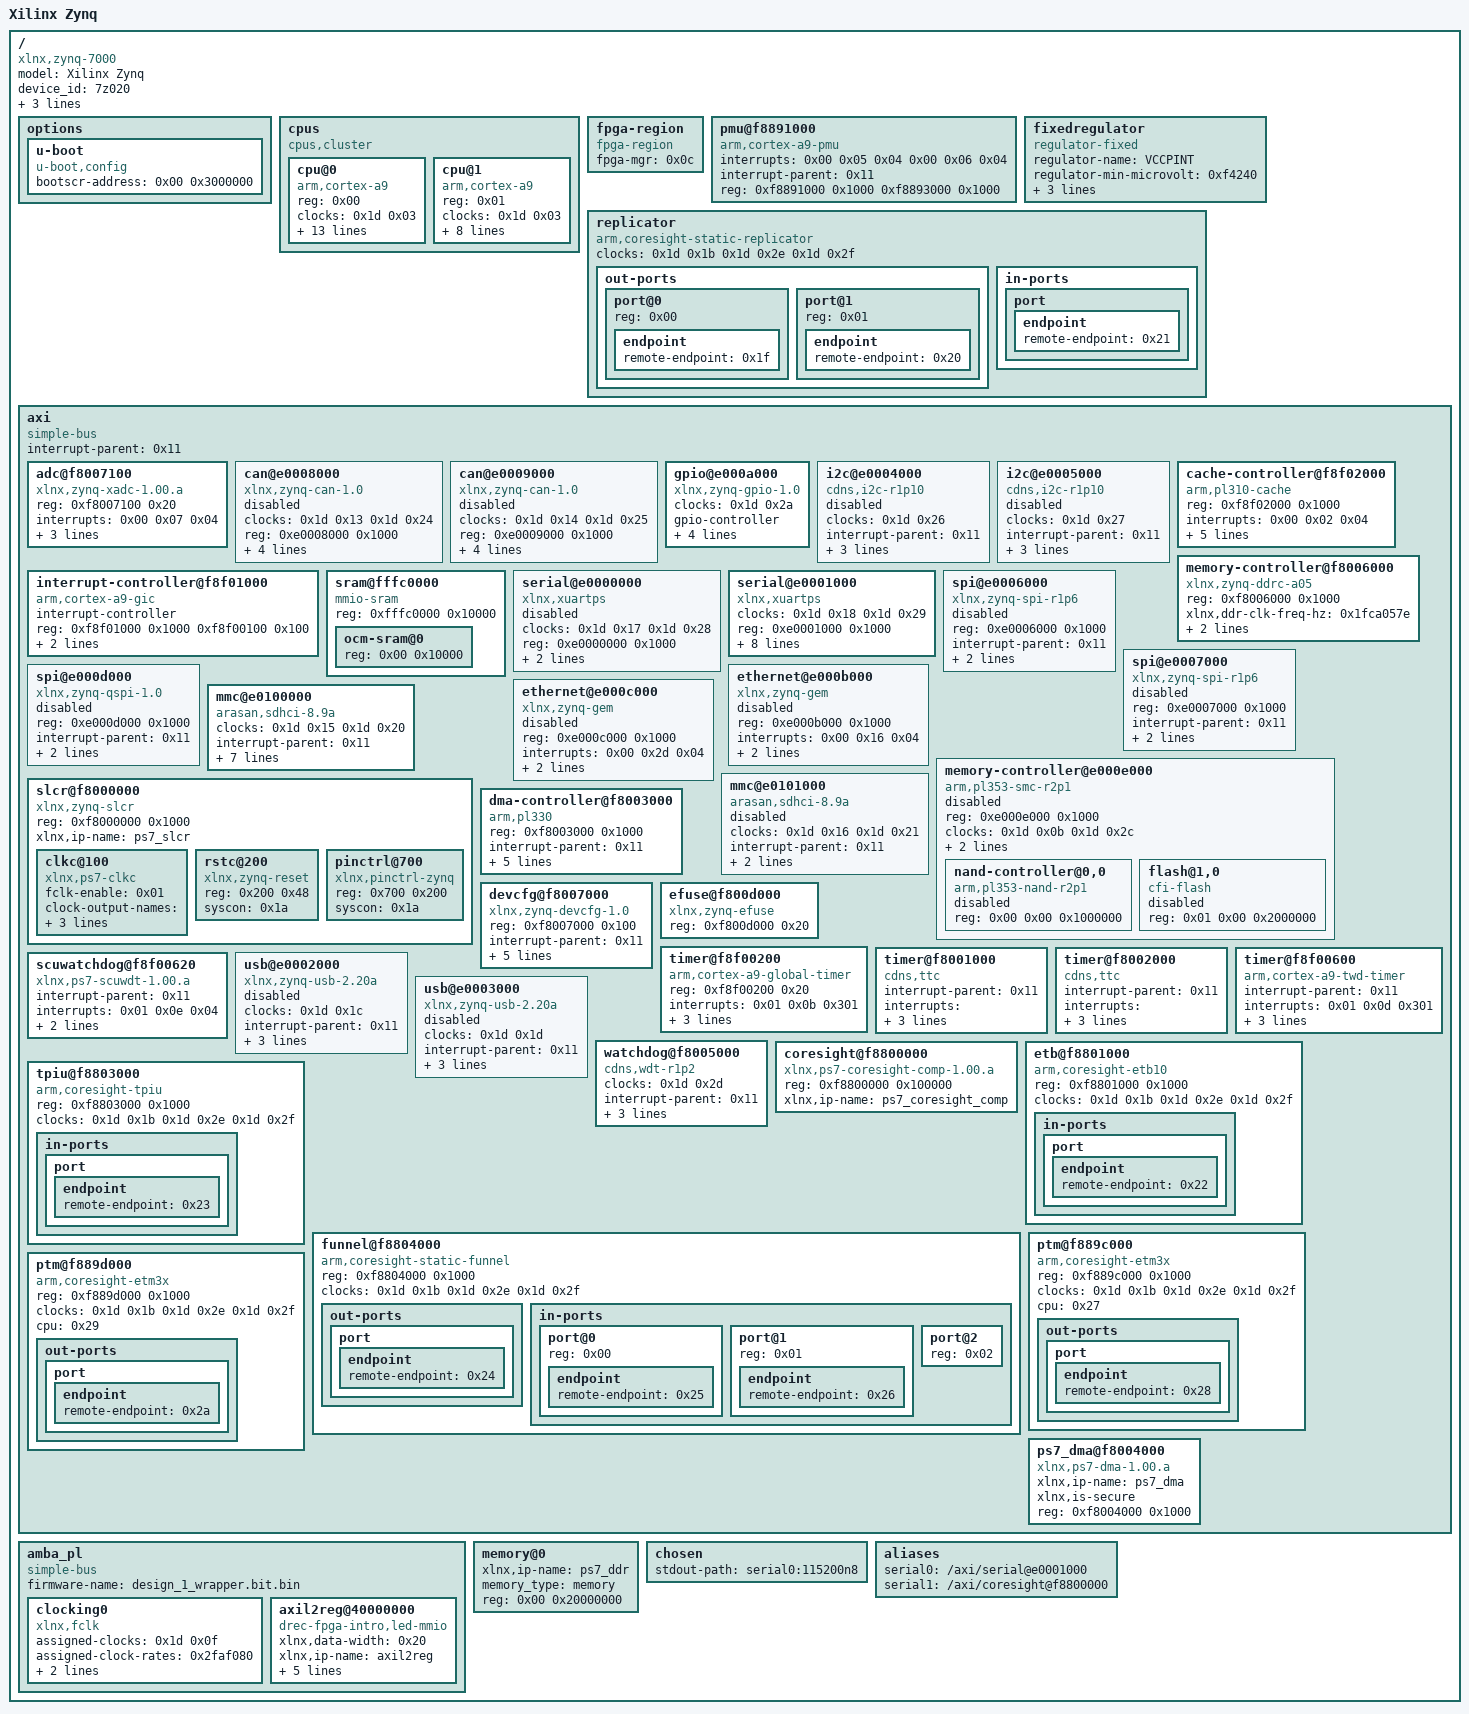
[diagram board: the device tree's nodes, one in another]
/dts-v1/;

/ {
	#address-cells = <0x01>;
	#size-cells = <0x01>;
	compatible = "xlnx,zynq-7000";
	model = "Xilinx Zynq";
	device_id = "7z020";
	slrcount = <0x01>;
	family = "Zynq";
	speed_grade = "2";

	options {

		u-boot {
			compatible = "u-boot,config";
			bootscr-address = <0x00 0x3000000>;
		};
	};

	cpus {
		#address-cells = <0x01>;
		#size-cells = <0x00>;
		compatible = "cpus,cluster";
		#ranges-address-cells = <0x01>;
		#ranges-size-cells = <0x01>;
		phandle = <0x2b>;

		cpu@0 {
			compatible = "arm,cortex-a9";
			device_type = "cpu";
			reg = <0x00>;
			clocks = <0x1d 0x03>;
			clock-latency = <0x3e8>;
			cpu0-supply = <0x1e>;
			operating-points = <0xa2c2b 0xf4240 0x51616 0xf4240>;
			xlnx,i-cache-size = <0x8000>;
			xlnx,d-cache-line-size = <0x14>;
			xlnx,i-cache-line-size = <0x14>;
			xlnx,cpu-1x-clk-freq-hz = <0x69f6bcb>;
			xlnx,ip-name = "ps7_cortexa9";
			xlnx,d-cache-size = <0x8000>;
			xlnx,num-cores = <0x02>;
			xlnx,cpu-clk-freq-hz = <0x27bc86bf>;
			bus-handle = <0x01>;
			phandle = <0x27>;
		};

		cpu@1 {
			compatible = "arm,cortex-a9";
			device_type = "cpu";
			reg = <0x01>;
			clocks = <0x1d 0x03>;
			xlnx,i-cache-size = <0x8000>;
			xlnx,d-cache-line-size = <0x14>;
			xlnx,i-cache-line-size = <0x14>;
			xlnx,cpu-1x-clk-freq-hz = <0x69f6bcb>;
			xlnx,ip-name = "ps7_cortexa9";
			xlnx,d-cache-size = <0x8000>;
			xlnx,cpu-clk-freq-hz = <0x27bc86bf>;
			bus-handle = <0x01>;
			phandle = <0x29>;
		};
	};

	fpga-region {
		compatible = "fpga-region";
		fpga-mgr = <0x0c>;
		#address-cells = <0x01>;
		#size-cells = <0x01>;
		ranges;
		phandle = <0x2c>;
	};

	pmu@f8891000 {
		compatible = "arm,cortex-a9-pmu";
		interrupts = <0x00 0x05 0x04 0x00 0x06 0x04>;
		interrupt-parent = <0x11>;
		reg = <0xf8891000 0x1000 0xf8893000 0x1000>;
	};

	fixedregulator {
		compatible = "regulator-fixed";
		regulator-name = "VCCPINT";
		regulator-min-microvolt = <0xf4240>;
		regulator-max-microvolt = <0xf4240>;
		regulator-boot-on;
		regulator-always-on;
		phandle = <0x1e>;
	};

	replicator {
		compatible = "arm,coresight-static-replicator";
		clocks = <0x1d 0x1b 0x1d 0x2e 0x1d 0x2f>;
		clock-names = "apb_pclk\0dbg_trc\0dbg_apb";

		out-ports {
			#address-cells = <0x01>;
			#size-cells = <0x00>;

			port@0 {
				reg = <0x00>;

				endpoint {
					remote-endpoint = <0x1f>;
					phandle = <0x23>;
				};
			};

			port@1 {
				reg = <0x01>;

				endpoint {
					remote-endpoint = <0x20>;
					phandle = <0x22>;
				};
			};
		};

		in-ports {

			port {

				endpoint {
					remote-endpoint = <0x21>;
					phandle = <0x24>;
				};
			};
		};
	};

	axi {
		bootph-all;
		compatible = "simple-bus";
		#address-cells = <0x01>;
		#size-cells = <0x01>;
		interrupt-parent = <0x11>;
		ranges;
		phandle = <0x01>;

		adc@f8007100 {
			compatible = "xlnx,zynq-xadc-1.00.a";
			reg = <0xf8007100 0x20>;
			interrupts = <0x00 0x07 0x04>;
			interrupt-parent = <0x11>;
			clocks = <0x1d 0x0c>;
			status = "okay";
			xlnx,ip-name = "ps7_xadc";
			phandle = <0x1c>;
		};

		can@e0008000 {
			compatible = "xlnx,zynq-can-1.0";
			status = "disabled";
			clocks = <0x1d 0x13 0x1d 0x24>;
			clock-names = "can_clk\0pclk";
			reg = <0xe0008000 0x1000>;
			interrupts = <0x00 0x1c 0x04>;
			interrupt-parent = <0x11>;
			tx-fifo-depth = <0x40>;
			rx-fifo-depth = <0x40>;
			phandle = <0x2d>;
		};

		can@e0009000 {
			compatible = "xlnx,zynq-can-1.0";
			status = "disabled";
			clocks = <0x1d 0x14 0x1d 0x25>;
			clock-names = "can_clk\0pclk";
			reg = <0xe0009000 0x1000>;
			interrupts = <0x00 0x33 0x04>;
			interrupt-parent = <0x11>;
			tx-fifo-depth = <0x40>;
			rx-fifo-depth = <0x40>;
			phandle = <0x2e>;
		};

		gpio@e000a000 {
			compatible = "xlnx,zynq-gpio-1.0";
			#gpio-cells = <0x02>;
			clocks = <0x1d 0x2a>;
			gpio-controller;
			interrupt-controller;
			#interrupt-cells = <0x02>;
			interrupt-parent = <0x11>;
			interrupts = <0x00 0x14 0x04>;
			reg = <0xe000a000 0x1000>;
			phandle = <0x2f>;
		};

		i2c@e0004000 {
			compatible = "cdns,i2c-r1p10";
			status = "disabled";
			clocks = <0x1d 0x26>;
			interrupt-parent = <0x11>;
			interrupts = <0x00 0x19 0x04>;
			clock-frequency = <0x61a80>;
			reg = <0xe0004000 0x1000>;
			#address-cells = <0x01>;
			#size-cells = <0x00>;
			phandle = <0x30>;
		};

		i2c@e0005000 {
			compatible = "cdns,i2c-r1p10";
			status = "disabled";
			clocks = <0x1d 0x27>;
			interrupt-parent = <0x11>;
			interrupts = <0x00 0x30 0x04>;
			clock-frequency = <0x61a80>;
			reg = <0xe0005000 0x1000>;
			#address-cells = <0x01>;
			#size-cells = <0x00>;
			phandle = <0x31>;
		};

		interrupt-controller@f8f01000 {
			compatible = "arm,cortex-a9-gic";
			#interrupt-cells = <0x03>;
			interrupt-controller;
			reg = <0xf8f01000 0x1000 0xf8f00100 0x100>;
			status = "okay";
			xlnx,irq-f2p-mode = "DIRECT";
			xlnx,ip-name = "ps7_intc_dist";
			phandle = <0x11>;
		};

		cache-controller@f8f02000 {
			compatible = "arm,pl310-cache";
			reg = <0xf8f02000 0x1000>;
			interrupts = <0x00 0x02 0x04>;
			arm,data-latency = <0x03 0x02 0x02>;
			arm,tag-latency = <0x02 0x02 0x02>;
			cache-unified;
			cache-level = <0x02>;
			status = "okay";
			xlnx,ip-name = "ps7_pl310";
			phandle = <0x13>;
		};

		memory-controller@f8006000 {
			compatible = "xlnx,zynq-ddrc-a05";
			reg = <0xf8006000 0x1000>;
			status = "okay";
			xlnx,ddr-clk-freq-hz = <0x1fca057e>;
			xlnx,ip-name = "ps7_ddrc";
			xlnx,has-ecc = <0x00>;
			phandle = <0x0b>;
		};

		sram@fffc0000 {
			compatible = "mmio-sram";
			reg = <0xfffc0000 0x10000>;
			#address-cells = <0x01>;
			#size-cells = <0x01>;
			ranges = <0x00 0xfffc0000 0x10000>;
			phandle = <0x32>;

			ocm-sram@0 {
				reg = <0x00 0x10000>;
			};
		};

		serial@e0000000 {
			compatible = "xlnx,xuartps\0cdns,uart-r1p8";
			status = "disabled";
			clocks = <0x1d 0x17 0x1d 0x28>;
			clock-names = "uart_clk\0pclk";
			reg = <0xe0000000 0x1000>;
			interrupts = <0x00 0x1b 0x04>;
			interrupt-parent = <0x11>;
			phandle = <0x33>;
		};

		serial@e0001000 {
			compatible = "xlnx,xuartps\0cdns,uart-r1p8";
			status = "okay";
			clocks = <0x1d 0x18 0x1d 0x29>;
			clock-names = "uart_clk\0pclk";
			reg = <0xe0001000 0x1000>;
			interrupts = <0x00 0x32 0x04>;
			interrupt-parent = <0x11>;
			xlnx,clock-freq = <0x5f5e100>;
			xlnx,has-modem = <0x00>;
			xlnx,ip-name = "ps7_uart";
			cts-override;
			port-number = <0x00>;
			xlnx,uart-clk-freq-hz = <0x5f5e100>;
			phandle = <0x1b>;
		};

		spi@e0006000 {
			compatible = "xlnx,zynq-spi-r1p6";
			reg = <0xe0006000 0x1000>;
			status = "disabled";
			interrupt-parent = <0x11>;
			interrupts = <0x00 0x1a 0x04>;
			clocks = <0x1d 0x19 0x1d 0x22>;
			clock-names = "ref_clk\0pclk";
			#address-cells = <0x01>;
			#size-cells = <0x00>;
			phandle = <0x34>;
		};

		spi@e0007000 {
			compatible = "xlnx,zynq-spi-r1p6";
			reg = <0xe0007000 0x1000>;
			status = "disabled";
			interrupt-parent = <0x11>;
			interrupts = <0x00 0x31 0x04>;
			clocks = <0x1d 0x1a 0x1d 0x23>;
			clock-names = "ref_clk\0pclk";
			#address-cells = <0x01>;
			#size-cells = <0x00>;
			phandle = <0x35>;
		};

		spi@e000d000 {
			compatible = "xlnx,zynq-qspi-1.0";
			reg = <0xe000d000 0x1000>;
			interrupt-parent = <0x11>;
			interrupts = <0x00 0x13 0x04>;
			clocks = <0x1d 0x0a 0x1d 0x2b>;
			clock-names = "ref_clk\0pclk";
			status = "disabled";
			#address-cells = <0x01>;
			#size-cells = <0x00>;
			phandle = <0x36>;
		};

		ethernet@e000b000 {
			compatible = "xlnx,zynq-gem\0cdns,gem";
			reg = <0xe000b000 0x1000>;
			status = "disabled";
			interrupts = <0x00 0x16 0x04>;
			interrupt-parent = <0x11>;
			clocks = <0x1d 0x1e 0x1d 0x1e 0x1d 0x0d>;
			clock-names = "pclk\0hclk\0tx_clk";
			#address-cells = <0x01>;
			#size-cells = <0x00>;
			phandle = <0x37>;
		};

		ethernet@e000c000 {
			compatible = "xlnx,zynq-gem\0cdns,gem";
			reg = <0xe000c000 0x1000>;
			status = "disabled";
			interrupts = <0x00 0x2d 0x04>;
			interrupt-parent = <0x11>;
			clocks = <0x1d 0x1f 0x1d 0x1f 0x1d 0x0e>;
			clock-names = "pclk\0hclk\0tx_clk";
			#address-cells = <0x01>;
			#size-cells = <0x00>;
			phandle = <0x38>;
		};

		memory-controller@e000e000 {
			compatible = "arm,pl353-smc-r2p1\0arm,primecell";
			reg = <0xe000e000 0x1000>;
			status = "disabled";
			clock-names = "memclk\0apb_pclk";
			clocks = <0x1d 0x0b 0x1d 0x2c>;
			ranges = <0x00 0x00 0xe1000000 0x1000000 0x01 0x00 0xe2000000 0x2000000 0x02 0x00 0xe4000000 0x2000000>;
			#address-cells = <0x02>;
			#size-cells = <0x01>;
			interrupt-parent = <0x11>;
			interrupts = <0x00 0x12 0x04>;
			phandle = <0x39>;

			nand-controller@0,0 {
				compatible = "arm,pl353-nand-r2p1";
				reg = <0x00 0x00 0x1000000>;
				status = "disabled";
				phandle = <0x3a>;
			};

			flash@1,0 {
				status = "disabled";
				compatible = "cfi-flash";
				reg = <0x01 0x00 0x2000000>;
				phandle = <0x3b>;
			};
		};

		mmc@e0100000 {
			compatible = "arasan,sdhci-8.9a";
			status = "okay";
			clock-names = "clk_xin\0clk_ahb";
			clocks = <0x1d 0x15 0x1d 0x20>;
			interrupt-parent = <0x11>;
			interrupts = <0x00 0x18 0x04>;
			reg = <0xe0100000 0x1000>;
			xlnx,has-power = <0x00>;
			xlnx,ip-name = "ps7_sdio";
			xlnx,sdio-clk-freq-hz = <0x5f5e100>;
			xlnx,has-wp = <0x00>;
			xlnx,has-cd = <0x00>;
			phandle = <0x19>;
		};

		mmc@e0101000 {
			compatible = "arasan,sdhci-8.9a";
			status = "disabled";
			clock-names = "clk_xin\0clk_ahb";
			clocks = <0x1d 0x16 0x1d 0x21>;
			interrupt-parent = <0x11>;
			interrupts = <0x00 0x2f 0x04>;
			reg = <0xe0101000 0x1000>;
			phandle = <0x3c>;
		};

		slcr@f8000000 {
			bootph-all;
			#address-cells = <0x01>;
			#size-cells = <0x01>;
			compatible = "xlnx,zynq-slcr\0syscon\0simple-mfd";
			reg = <0xf8000000 0x1000>;
			ranges;
			status = "okay";
			xlnx,ip-name = "ps7_slcr";
			phandle = <0x1a>;

			clkc@100 {
				bootph-all;
				#clock-cells = <0x01>;
				compatible = "xlnx,ps7-clkc";
				fclk-enable = <0x01>;
				clock-output-names = "armpll\0ddrpll\0iopll\0cpu_6or4x\0cpu_3or2x\0cpu_2x\0cpu_1x\0ddr2x\0ddr3x\0dci\0lqspi\0smc\0pcap\0gem0\0gem1\0fclk0\0fclk1\0fclk2\0fclk3\0can0\0can1\0sdio0\0sdio1\0uart0\0uart1\0spi0\0spi1\0dma\0usb0_aper\0usb1_aper\0gem0_aper\0gem1_aper\0sdio0_aper\0sdio1_aper\0spi0_aper\0spi1_aper\0can0_aper\0can1_aper\0i2c0_aper\0i2c1_aper\0uart0_aper\0uart1_aper\0gpio_aper\0lqspi_aper\0smc_aper\0swdt\0dbg_trc\0dbg_apb";
				reg = <0x100 0x100>;
				ps-clk-frequency = <0x1fca055>;
				phandle = <0x1d>;
			};

			rstc@200 {
				compatible = "xlnx,zynq-reset";
				reg = <0x200 0x48>;
				#reset-cells = <0x01>;
				syscon = <0x1a>;
				phandle = <0x3d>;
			};

			pinctrl@700 {
				compatible = "xlnx,pinctrl-zynq";
				reg = <0x700 0x200>;
				syscon = <0x1a>;
				phandle = <0x3e>;
			};
		};

		dma-controller@f8003000 {
			compatible = "arm,pl330\0arm,primecell";
			reg = <0xf8003000 0x1000>;
			interrupt-parent = <0x11>;
			interrupts = <0x00 0x0d 0x04 0x00 0x0e 0x04 0x00 0x0f 0x04 0x00 0x10 0x04 0x00 0x11 0x04 0x00 0x28 0x04 0x00 0x29 0x04 0x00 0x2a 0x04 0x00 0x2b 0x04>;
			#dma-cells = <0x01>;
			clocks = <0x1d 0x1b>;
			clock-names = "apb_pclk";
			status = "okay";
			xlnx,ip-name = "ps7_dma";
			xlnx,is-secure;
			phandle = <0x0e>;
		};

		devcfg@f8007000 {
			compatible = "xlnx,zynq-devcfg-1.0";
			reg = <0xf8007000 0x100>;
			interrupt-parent = <0x11>;
			interrupts = <0x00 0x08 0x04>;
			clocks = <0x1d 0x0c 0x1d 0x0f 0x1d 0x10 0x1d 0x11 0x1d 0x12>;
			clock-names = "ref_clk\0fclk0\0fclk1\0fclk2\0fclk3";
			syscon = <0x1a>;
			status = "okay";
			xlnx,ip-name = "ps7_dev_cfg";
			phandle = <0x0c>;
		};

		efuse@f800d000 {
			compatible = "xlnx,zynq-efuse";
			reg = <0xf800d000 0x20>;
			phandle = <0x3f>;
		};

		timer@f8f00200 {
			compatible = "arm,cortex-a9-global-timer";
			reg = <0xf8f00200 0x20>;
			interrupts = <0x01 0x0b 0x301>;
			interrupt-parent = <0x11>;
			clocks = <0x1d 0x04>;
			status = "okay";
			xlnx,ip-name = "ps7_globaltimer";
			phandle = <0x0f>;
		};

		timer@f8001000 {
			interrupt-parent = <0x11>;
			interrupts = <0x00 0x0a 0x04 0x00 0x0b 0x04 0x00 0x0c 0x04>;
			compatible = "cdns,ttc";
			clocks = <0x1d 0x06>;
			reg = <0xf8001000 0x1000>;
			phandle = <0x40>;
		};

		timer@f8002000 {
			interrupt-parent = <0x11>;
			interrupts = <0x00 0x25 0x04 0x00 0x26 0x04 0x00 0x27 0x04>;
			compatible = "cdns,ttc";
			clocks = <0x1d 0x06>;
			reg = <0xf8002000 0x1000>;
			phandle = <0x41>;
		};

		timer@f8f00600 {
			bootph-all;
			interrupt-parent = <0x11>;
			interrupts = <0x01 0x0d 0x301>;
			compatible = "arm,cortex-a9-twd-timer";
			reg = <0xf8f00600 0x20>;
			clocks = <0x1d 0x04>;
			status = "okay";
			xlnx,ip-name = "ps7_scutimer";
			phandle = <0x17>;
		};

		scuwatchdog@f8f00620 {
			interrupt-parent = <0x11>;
			interrupts = <0x01 0x0e 0x04>;
			compatible = "xlnx,ps7-scuwdt-1.00.a";
			reg = <0xf8f00620 0xe0>;
			status = "okay";
			xlnx,ip-name = "ps7_scuwdt";
			phandle = <0x18>;
		};

		usb@e0002000 {
			compatible = "xlnx,zynq-usb-2.20a\0chipidea,usb2";
			status = "disabled";
			clocks = <0x1d 0x1c>;
			interrupt-parent = <0x11>;
			interrupts = <0x00 0x15 0x04>;
			reg = <0xe0002000 0x1000>;
			phy_type = "ulpi";
			phandle = <0x42>;
		};

		usb@e0003000 {
			compatible = "xlnx,zynq-usb-2.20a\0chipidea,usb2";
			status = "disabled";
			clocks = <0x1d 0x1d>;
			interrupt-parent = <0x11>;
			interrupts = <0x00 0x2c 0x04>;
			reg = <0xe0003000 0x1000>;
			phy_type = "ulpi";
			phandle = <0x43>;
		};

		watchdog@f8005000 {
			clocks = <0x1d 0x2d>;
			compatible = "cdns,wdt-r1p2";
			interrupt-parent = <0x11>;
			interrupts = <0x00 0x09 0x01>;
			reg = <0xf8005000 0x1000>;
			timeout-sec = <0x0a>;
			phandle = <0x44>;
		};

		coresight@f8800000 {
			compatible = "xlnx,ps7-coresight-comp-1.00.a";
			status = "okay";
			reg = <0xf8800000 0x100000>;
			xlnx,ip-name = "ps7_coresight_comp";
			phandle = <0x0a>;
		};

		etb@f8801000 {
			compatible = "arm,coresight-etb10\0arm,primecell";
			reg = <0xf8801000 0x1000>;
			clocks = <0x1d 0x1b 0x1d 0x2e 0x1d 0x2f>;
			clock-names = "apb_pclk\0dbg_trc\0dbg_apb";

			in-ports {

				port {

					endpoint {
						remote-endpoint = <0x22>;
						phandle = <0x20>;
					};
				};
			};
		};

		tpiu@f8803000 {
			compatible = "arm,coresight-tpiu\0arm,primecell";
			reg = <0xf8803000 0x1000>;
			clocks = <0x1d 0x1b 0x1d 0x2e 0x1d 0x2f>;
			clock-names = "apb_pclk\0dbg_trc\0dbg_apb";

			in-ports {

				port {

					endpoint {
						remote-endpoint = <0x23>;
						phandle = <0x1f>;
					};
				};
			};
		};

		funnel@f8804000 {
			compatible = "arm,coresight-static-funnel\0arm,primecell";
			reg = <0xf8804000 0x1000>;
			clocks = <0x1d 0x1b 0x1d 0x2e 0x1d 0x2f>;
			clock-names = "apb_pclk\0dbg_trc\0dbg_apb";

			out-ports {

				port {

					endpoint {
						remote-endpoint = <0x24>;
						phandle = <0x21>;
					};
				};
			};

			in-ports {
				#address-cells = <0x01>;
				#size-cells = <0x00>;

				port@0 {
					reg = <0x00>;

					endpoint {
						remote-endpoint = <0x25>;
						phandle = <0x28>;
					};
				};

				port@1 {
					reg = <0x01>;

					endpoint {
						remote-endpoint = <0x26>;
						phandle = <0x2a>;
					};
				};

				port@2 {
					reg = <0x02>;
				};
			};
		};

		ptm@f889c000 {
			compatible = "arm,coresight-etm3x\0arm,primecell";
			reg = <0xf889c000 0x1000>;
			clocks = <0x1d 0x1b 0x1d 0x2e 0x1d 0x2f>;
			clock-names = "apb_pclk\0dbg_trc\0dbg_apb";
			cpu = <0x27>;

			out-ports {

				port {

					endpoint {
						remote-endpoint = <0x28>;
						phandle = <0x25>;
					};
				};
			};
		};

		ptm@f889d000 {
			compatible = "arm,coresight-etm3x\0arm,primecell";
			reg = <0xf889d000 0x1000>;
			clocks = <0x1d 0x1b 0x1d 0x2e 0x1d 0x2f>;
			clock-names = "apb_pclk\0dbg_trc\0dbg_apb";
			cpu = <0x29>;

			out-ports {

				port {

					endpoint {
						remote-endpoint = <0x2a>;
						phandle = <0x26>;
					};
				};
			};
		};

		ps7_dma@f8004000 {
			compatible = "xlnx,ps7-dma-1.00.a";
			status = "okay";
			xlnx,ip-name = "ps7_dma";
			xlnx,is-secure;
			reg = <0xf8004000 0x1000>;
			phandle = <0x0d>;
		};
	};

	amba_pl {
		ranges;
		compatible = "simple-bus";
		#address-cells = <0x01>;
		#size-cells = <0x01>;
		firmware-name = "design_1_wrapper.bit.bin";
		phandle = <0x49>;

		clocking0 {
			compatible = "xlnx,fclk";
			assigned-clocks = <0x1d 0x0f>;
			assigned-clock-rates = <0x2faf080>;
			#clock-cells = <0x00>;
			clock-output-names = "fabric_clk";
			clocks = <0x1d 0x0f>;
			phandle = <0x4a>;
		};

		axil2reg@40000000 {
			compatible = "drec-fpga-intro,led-mmio";
			status = "okay";
			clock-names = "clk";
			xlnx,data-width = <0x20>;
			xlnx,ip-name = "axil2reg";
			xlnx,strb-width = <0x04>;
			xlnx,edk-iptype = "PERIPHERAL";
			xlnx,addr-width = <0x20>;
			reg = <0x40000000 0x1000>;
			clocks = <0x1d 0x0f>;
			phandle = <0x05>;
		};
	};

	memory@0 {
		xlnx,ip-name = "ps7_ddr";
		device_type = "memory";
		memory_type = "memory";
		reg = <0x00 0x20000000>;
		phandle = <0x02>;
	};

	chosen {
		stdout-path = "serial0:115200n8";
	};

	aliases {
		serial0 = "/axi/serial@e0001000";
		serial1 = "/axi/coresight@f8800000";
	};

	__symbols__ {
		cpus_a9 = "/cpus-a9@0";
		ps7_cortexa9_0 = "/cpus-a9@0/cpu@0";
		ps7_cortexa9_1 = "/cpus-a9@0/cpu@1";
		fpga_full = "/fpga-region";
		regulator_vccpint = "/fixedregulator";
		replicator_out_port0 = "/replicator/out-ports/port@0/endpoint";
		replicator_out_port1 = "/replicator/out-ports/port@1/endpoint";
		replicator_in_port0 = "/replicator/in-ports/port/endpoint";
		amba = "/axi";
		adc = "/axi/adc@f8007100";
		can0 = "/axi/can@e0008000";
		can1 = "/axi/can@e0009000";
		gpio0 = "/axi/gpio@e000a000";
		i2c0 = "/axi/i2c@e0004000";
		i2c1 = "/axi/i2c@e0005000";
		intc = "/axi/interrupt-controller@f8f01000";
		L2 = "/axi/cache-controller@f8f02000";
		mc = "/axi/memory-controller@f8006000";
		ocm = "/axi/sram@fffc0000";
		uart0 = "/axi/serial@e0000000";
		uart1 = "/axi/serial@e0001000";
		spi0 = "/axi/spi@e0006000";
		spi1 = "/axi/spi@e0007000";
		qspi = "/axi/spi@e000d000";
		gem0 = "/axi/ethernet@e000b000";
		gem1 = "/axi/ethernet@e000c000";
		smcc = "/axi/memory-controller@e000e000";
		nfc0 = "/axi/memory-controller@e000e000/nand-controller@0,0";
		nor0 = "/axi/memory-controller@e000e000/flash@1,0";
		sdhci0 = "/axi/mmc@e0100000";
		sdhci1 = "/axi/mmc@e0101000";
		slcr = "/axi/slcr@f8000000";
		clkc = "/axi/slcr@f8000000/clkc@100";
		rstc = "/axi/slcr@f8000000/rstc@200";
		pinctrl0 = "/axi/slcr@f8000000/pinctrl@700";
		dmac_s = "/axi/dma-controller@f8003000";
		devcfg = "/axi/devcfg@f8007000";
		efuse = "/axi/efuse@f800d000";
		global_timer = "/axi/timer@f8f00200";
		ttc0 = "/axi/timer@f8001000";
		ttc1 = "/axi/timer@f8002000";
		scutimer = "/axi/timer@f8f00600";
		scuwdt = "/axi/scuwatchdog@f8f00620";
		usb0 = "/axi/usb@e0002000";
		usb1 = "/axi/usb@e0003000";
		watchdog0 = "/axi/watchdog@f8005000";
		coresight = "/axi/coresight@f8800000";
		etb_in_port = "/axi/etb@f8801000/in-ports/port/endpoint";
		tpiu_in_port = "/axi/tpiu@f8803000/in-ports/port/endpoint";
		funnel_out_port = "/axi/funnel@f8804000/out-ports/port/endpoint";
		funnel0_in_port0 = "/axi/funnel@f8804000/in-ports/port@0/endpoint";
		funnel0_in_port1 = "/axi/funnel@f8804000/in-ports/port@1/endpoint";
		ptm0_out_port = "/axi/ptm@f889c000/out-ports/port/endpoint";
		ptm1_out_port = "/axi/ptm@f889d000/out-ports/port/endpoint";
		ps7_dma_ns = "/axi/ps7_dma@f8004000";
		amba_pl = "/amba_pl";
		clocking0 = "/amba_pl/clocking0";
		axil2reg_0 = "/amba_pl/axil2reg@40000000";
		ps7_ddr_0_memory = "/memory@00100000";
	};
};
